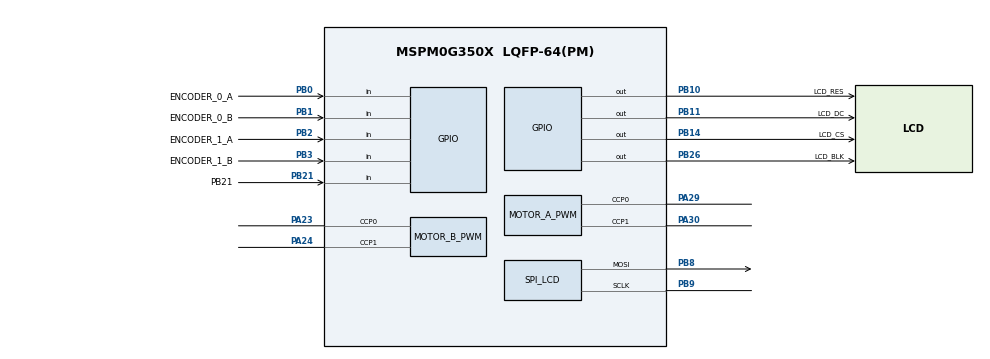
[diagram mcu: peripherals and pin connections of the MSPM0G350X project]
/**
 * @cliArgs --device "MSPM0G350X" --part "Default" --package "LQFP-64(PM)" --product "mspm0_sdk@2.10.00.04"
 * @versions {"tool":"1.26.2+4477"}
 */

const GPIO          = scripting.addModule("/ti/driverlib/GPIO", {}, false);
const USER_BUTTON   = GPIO.addInstance();
const ENCODER_GPIOB = GPIO.addInstance();
const LCD_CTRL      = GPIO.addInstance();
const PWM           = scripting.addModule("/ti/driverlib/PWM", {}, false);
const MOTOR_A_PWM   = PWM.addInstance();
const MOTOR_B_PWM   = PWM.addInstance();
const SPI           = scripting.addModule("/ti/driverlib/SPI", {}, false);
const SPI_LCD       = SPI.addInstance();
const SYSCTL        = scripting.addModule("/ti/driverlib/SYSCTL");
const SYSTICK       = scripting.addModule("/ti/driverlib/SYSTICK");
const ProjectConfig = scripting.addModule("/ti/project_config/ProjectConfig");

const divider9       = system.clockTree["UDIV"];
divider9.divideValue = 2;

const mux4       = system.clockTree["EXHFMUX"];
mux4.inputSelect = "EXHFMUX_XTAL";

const mux8       = system.clockTree["HSCLKMUX"];
mux8.inputSelect = "HSCLKMUX_SYSPLL2X";

const mux12       = system.clockTree["SYSPLLMUX"];
mux12.inputSelect = "zSYSPLLMUX_HFCLK";

const hfxIn       = system.clockTree["HFXT"];
hfxIn.inputFreq   = 40;
hfxIn.HFXTStartup = 10;
hfxIn.enable      = true;

USER_BUTTON.$name                              = "USER_BUTTON";
USER_BUTTON.associatedPins[0].$name            = "PB21";
USER_BUTTON.associatedPins[0].direction        = "INPUT";
USER_BUTTON.associatedPins[0].internalResistor = "PULL_UP";
USER_BUTTON.associatedPins[0].pin.$assign      = "PB21";

MOTOR_A_PWM.$name                              = "MOTOR_A_PWM";
MOTOR_A_PWM.timerStartTimer                    = false;
MOTOR_A_PWM.clockPrescale                      = 4;
MOTOR_A_PWM.peripheral.$assign                 = "TIMG6";
MOTOR_A_PWM.peripheral.ccp0Pin.$assign         = "PA29";
MOTOR_A_PWM.peripheral.ccp1Pin.$assign         = "PA30";
MOTOR_A_PWM.PWM_CHANNEL_0.$name                = "MOTOR_A_IN1_PWM";
MOTOR_A_PWM.PWM_CHANNEL_1.$name                = "MOTOR_A_IN2_PWM";
MOTOR_A_PWM.ccp0PinConfig.direction            = scripting.forceWrite("OUTPUT");
MOTOR_A_PWM.ccp0PinConfig.hideOutputInversion  = scripting.forceWrite(false);
MOTOR_A_PWM.ccp0PinConfig.onlyInternalResistor = scripting.forceWrite(false);
MOTOR_A_PWM.ccp0PinConfig.passedPeripheralType = scripting.forceWrite("Digital");
MOTOR_A_PWM.ccp0PinConfig.$name                = "MOTOR_A_IN1_PIN";
MOTOR_A_PWM.ccp1PinConfig.direction            = scripting.forceWrite("OUTPUT");
MOTOR_A_PWM.ccp1PinConfig.hideOutputInversion  = scripting.forceWrite(false);
MOTOR_A_PWM.ccp1PinConfig.onlyInternalResistor = scripting.forceWrite(false);
MOTOR_A_PWM.ccp1PinConfig.passedPeripheralType = scripting.forceWrite("Digital");
MOTOR_A_PWM.ccp1PinConfig.$name                = "MOTOR_A_IN2_PIN";

MOTOR_B_PWM.$name                              = "MOTOR_B_PWM";
MOTOR_B_PWM.timerStartTimer                    = false;
MOTOR_B_PWM.clockPrescale                      = 4;
MOTOR_B_PWM.peripheral.$assign                 = "TIMG7";
MOTOR_B_PWM.peripheral.ccp0Pin.$assign         = "PA23";
MOTOR_B_PWM.peripheral.ccp1Pin.$assign         = "PA24";
MOTOR_B_PWM.PWM_CHANNEL_0.$name                = "MOTOR_B_IN1_PWM";
MOTOR_B_PWM.PWM_CHANNEL_1.$name                = "MOTOR_B_IN2_PWM";
MOTOR_B_PWM.ccp0PinConfig.direction            = scripting.forceWrite("OUTPUT");
MOTOR_B_PWM.ccp0PinConfig.hideOutputInversion  = scripting.forceWrite(false);
MOTOR_B_PWM.ccp0PinConfig.onlyInternalResistor = scripting.forceWrite(false);
MOTOR_B_PWM.ccp0PinConfig.passedPeripheralType = scripting.forceWrite("Digital");
MOTOR_B_PWM.ccp0PinConfig.$name                = "MOTOR_B_IN1_PIN";
MOTOR_B_PWM.ccp1PinConfig.direction            = scripting.forceWrite("OUTPUT");
MOTOR_B_PWM.ccp1PinConfig.hideOutputInversion  = scripting.forceWrite(false);
MOTOR_B_PWM.ccp1PinConfig.onlyInternalResistor = scripting.forceWrite(false);
MOTOR_B_PWM.ccp1PinConfig.passedPeripheralType = scripting.forceWrite("Digital");
MOTOR_B_PWM.ccp1PinConfig.$name                = "MOTOR_B_IN2_PIN";

ENCODER_GPIOB.$name                         = "ENCODER_GPIOB";
ENCODER_GPIOB.associatedPins.create(4);
ENCODER_GPIOB.associatedPins[0].$name       = "ENCODER_0_A";
ENCODER_GPIOB.associatedPins[0].direction   = "INPUT";
ENCODER_GPIOB.associatedPins[0].interruptEn = true;
ENCODER_GPIOB.associatedPins[0].polarity    = "RISE_FALL";
ENCODER_GPIOB.associatedPins[0].pin.$assign = "PB0";
ENCODER_GPIOB.associatedPins[1].$name       = "ENCODER_0_B";
ENCODER_GPIOB.associatedPins[1].direction   = "INPUT";
ENCODER_GPIOB.associatedPins[1].interruptEn = true;
ENCODER_GPIOB.associatedPins[1].polarity    = "RISE_FALL";
ENCODER_GPIOB.associatedPins[1].pin.$assign = "PB1";
ENCODER_GPIOB.associatedPins[2].$name       = "ENCODER_1_A";
ENCODER_GPIOB.associatedPins[2].direction   = "INPUT";
ENCODER_GPIOB.associatedPins[2].interruptEn = true;
ENCODER_GPIOB.associatedPins[2].polarity    = "RISE_FALL";
ENCODER_GPIOB.associatedPins[2].pin.$assign = "PB2";
ENCODER_GPIOB.associatedPins[3].$name       = "ENCODER_1_B";
ENCODER_GPIOB.associatedPins[3].direction   = "INPUT";
ENCODER_GPIOB.associatedPins[3].interruptEn = true;
ENCODER_GPIOB.associatedPins[3].polarity    = "RISE_FALL";
ENCODER_GPIOB.associatedPins[3].pin.$assign = "PB3";

const Board = scripting.addModule("/ti/driverlib/Board", {}, false);

LCD_CTRL.$name                          = "LCD_CTRL";
LCD_CTRL.associatedPins.create(4);
LCD_CTRL.associatedPins[0].$name        = "LCD_RES";
LCD_CTRL.associatedPins[0].initialValue = "SET";
LCD_CTRL.associatedPins[0].pin.$assign  = "PB10";
LCD_CTRL.associatedPins[1].$name        = "LCD_DC";
LCD_CTRL.associatedPins[1].initialValue = "SET";
LCD_CTRL.associatedPins[1].pin.$assign  = "PB11";
LCD_CTRL.associatedPins[2].$name        = "LCD_CS";
LCD_CTRL.associatedPins[2].initialValue = "SET";
LCD_CTRL.associatedPins[2].pin.$assign  = "PB14";
LCD_CTRL.associatedPins[3].$name        = "LCD_BLK";
LCD_CTRL.associatedPins[3].initialValue = "SET";
LCD_CTRL.associatedPins[3].pin.$assign  = "PB26";

SPI_LCD.$name                                 = "SPI_LCD";
SPI_LCD.frameFormat                           = "MOTO3";
SPI_LCD.direction                             = "PICO";
SPI_LCD.targetBitRate                         = 20000000;
SPI_LCD.enabledDMAEvent2Triggers              = "DL_SPI_DMA_INTERRUPT_TX";
SPI_LCD.sclkPinConfig.direction               = scripting.forceWrite("OUTPUT");
SPI_LCD.sclkPinConfig.onlyInternalResistor    = scripting.forceWrite(false);
SPI_LCD.sclkPinConfig.passedPeripheralType    = scripting.forceWrite("Digital");
SPI_LCD.sclkPinConfig.$name                   = "ti_driverlib_gpio_GPIOPinGeneric0";
SPI_LCD.mosiPinConfig.direction               = scripting.forceWrite("OUTPUT");
SPI_LCD.mosiPinConfig.hideOutputInversion     = scripting.forceWrite(false);
SPI_LCD.mosiPinConfig.onlyInternalResistor    = scripting.forceWrite(false);
SPI_LCD.mosiPinConfig.passedPeripheralType    = scripting.forceWrite("Digital");
SPI_LCD.mosiPinConfig.$name                   = "ti_driverlib_gpio_GPIOPinGeneric1";
SPI_LCD.peripheral.$assign                    = "SPI1";
SPI_LCD.peripheral.sclkPin.$assign            = "PB9";
SPI_LCD.peripheral.mosiPin.$assign            = "PB8";
SPI_LCD.DMA_CHANNEL_EVENT2.$name              = "DMA_CH2";
SPI_LCD.DMA_CHANNEL_EVENT2.enableInterrupt    = true;
SPI_LCD.DMA_CHANNEL_EVENT2.dstLength          = "BYTE";
SPI_LCD.DMA_CHANNEL_EVENT2.srcLength          = "BYTE";
SPI_LCD.DMA_CHANNEL_EVENT2.addressMode        = "b2f";
SPI_LCD.DMA_CHANNEL_EVENT2.peripheral.$assign = "DMA_CH2";

SYSCTL.clockTreeEn = true;

SYSTICK.periodEnable    = true;
SYSTICK.interruptEnable = true;
SYSTICK.systickEnable   = true;
SYSTICK.period          = 80000;

ProjectConfig.genLibCMSIS = false;

hfxIn.peripheral.$suggestSolution          = "SYSCTL";
hfxIn.peripheral.hfxInPin.$suggestSolution = "PA5";
hfxIn.peripheral.hfxOutPin.$suggestSolution = "PA6";
Board.peripheral.$suggestSolution           = "DEBUGSS";
Board.peripheral.swclkPin.$suggestSolution  = "PA20";
Board.peripheral.swdioPin.$suggestSolution  = "PA19";
